# cslr_tetb register map
Vendor: Texas Instruments
Peripheral module from a debugger description file (folder TCI6484_C6457).
Registers are 32-bit, access not given, reset 0x0 unless marked. A register's access mark holds for its fields unless they carry their own. Offsets are as the file gives them; lines under a group give offsets from that group; [hi:lo] are bit positions; {n}, {i} and the like mark numbered series; 'fields as' and 'values as' point back to an identical list; <NAME> marks a mode.

## TETB — TI External Trace Buffer
0x04 RDP ro reset 0x200 — RAM Depth Register
  [31:0] RDP — RAM Depth
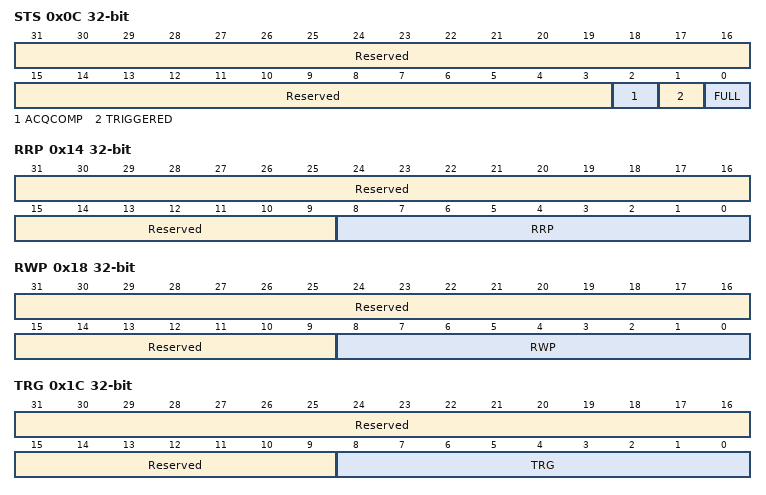
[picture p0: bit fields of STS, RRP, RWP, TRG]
0x0C STS — Status Register
  [31:3] Reserved — (access N)
  [2] ACQCOMP ro — Acquisition complete
  [1] TRIGGERED ro — Trigger bit set when a trigger has been observed
  [0] FULL ro — RAM Full (RAM write pointer has wrapped around)
0x10 RRD ro — RAM Read Data
  [31:0] RRD — RAM read Data
0x14 RRP — RAM Read Pointer register
  [31:9] Reserved — (access N)
  [8:0] RRP rw — RAM pointer register
0x18 RWP — RAM Write Pointer register
  [31:9] Reserved — (access N)
  [8:0] RWP rw — RAM write pointer register
0x1C TRG — Trigger Counter Register
  [31:9] Reserved — (access N)
  [8:0] TRG rw — Trigger counter register
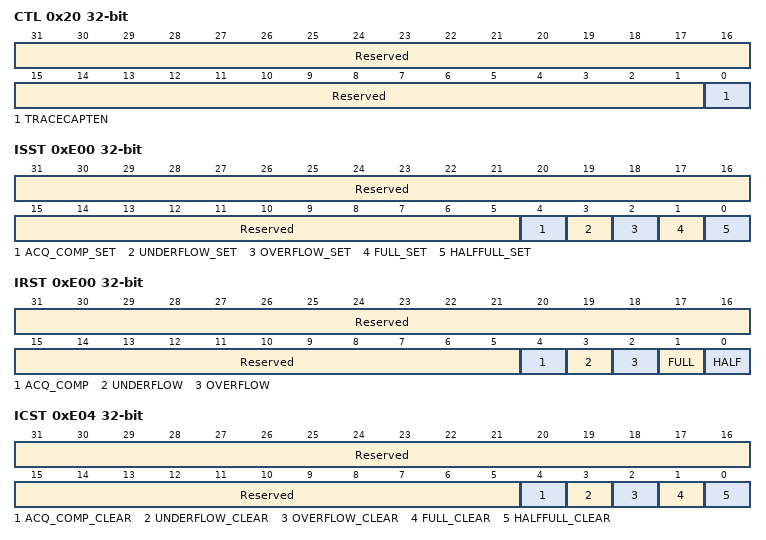
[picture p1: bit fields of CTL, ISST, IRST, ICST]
0x20 CTL — Control Register
  [31:1] Reserved — (access N)
  [0] TRACECAPTEN rw — TETB Trace Capture Enable/Disable
    0=DISABLE; 1=ENABLE
0x24 RWD rw — RAM write Data Register
  [31:0] RWD — Data written to TETB trace RAM
0xA00 RBD ro — RAM write Data Register
  [31:0] RBD — Data read from the TETB Trace RAM
0xE00 ISST — Interrupt Set Shadow Register
  [31:5] Reserved — (access N)
  [4] ACQ_COMP_SET wo — Acquisition complete
    1=SET (Set the AcqComp bit in the IRST)
  [3] UNDERFLOW_SET wo — It is set when RWP crosses the RRP
    1=SET (Set the underflow bit in the IRST)
  [2] OVERFLOW_SET wo — It is set when RWP crosses the RRP
    1=SET (Set the overflow bit in the IRST)
  [1] FULL_SET wo — It is set when RWP is rolls over from the maximum value back to 0. It is reset when the RRP rolls over from the maximum value back to 0.
    1=SET (Set the full bit in the IRST)
  [0] HALFFULL_SET wo — Indicates that the RAM is half full. It gets reset when the RRP crosses the half way point
    1=SET (Set the half full bit in the IRST)
0xE00 IRST — Interrupt Raw Status Register
  [31:5] Reserved — (access N)
  [4] ACQ_COMP ro — Acquisition complete
  [3] UNDERFLOW ro — It is set when RWP crosses the RRP
  [2] OVERFLOW ro — It is set when RWP crosses the RRP
  [1] FULL ro — It is set when RWP is rolls over from the maximum value back to 0. It is reset when the RRP rolls over from the maximum value back to 0.
  [0] HALF FULL ro — Indicates that the RAM is half full. It gets reset when the RRP crosses the half way point
0xE04 ICST — Interrupt Set Shadow Register
  [31:5] Reserved — (access N)
  [4] ACQ_COMP_CLEAR wo — Acquisition complete
    1=CLEAR (Clear the AcqComp bit in the IRST)
  [3] UNDERFLOW_CLEAR wo — It is set when RWP crosses the RRP
    1=CLEAR (Clear the underflow bit in the IRST)
  [2] OVERFLOW_CLEAR wo — It is set when RWP crosses the RRP
    1=CLEAR (Clear the overflow bit in the IRST)
  [1] FULL_CLEAR wo — It is set when RWP is rolls over from the maximum value back to 0. It is reset when the RRP rolls over from the maximum value back to 0.
    1=CLEAR (Clear the full bit in the IRST)
  [0] HALFFULL_CLEAR wo — Indicates that the RAM is half full. It gets reset when the RRP crosses the half way point
    1=CLEAR (Clear the half full bit in the IRST)
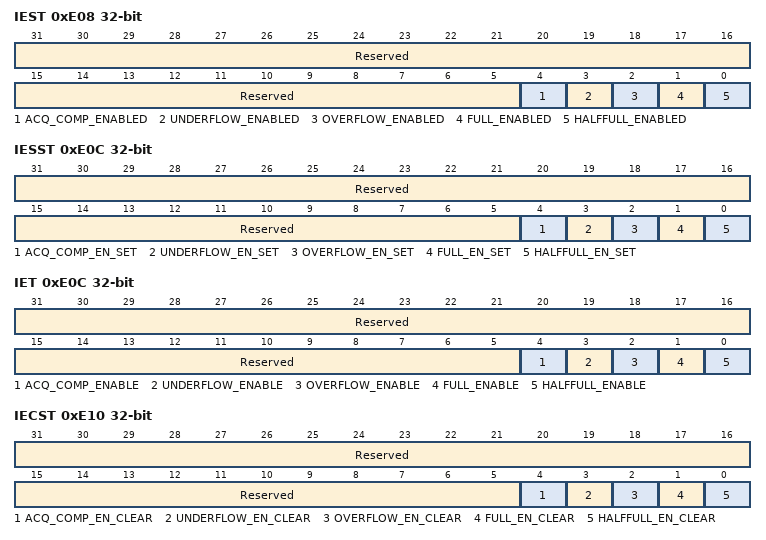
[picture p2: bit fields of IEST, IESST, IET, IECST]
0xE08 IEST — IRST qualified by the Interrupt Enable Register
  [31:5] Reserved — (access N)
  [4] ACQ_COMP_ENABLED ro — Qualified Acq_comp bit
  [3] UNDERFLOW_ENABLED ro — Qualified Underflow bit
  [2] OVERFLOW_ENABLED ro — Qualified Overflow bit
  [1] FULL_ENABLED ro — Qualified Full bit
  [0] HALFFULL_ENABLED ro — Qualified Half Full bit
0xE0C IESST — Enable interrupts in the IET register
  [31:5] Reserved — (access N)
  [4] ACQ_COMP_EN_SET wo — Set the Acquisition Complete bit in the IET
    1=SET (Set the Acquisition Comp bit in the IET)
  [3] UNDERFLOW_EN_SET wo — Set the underflow bit in the IET
    1=SET (set the underflow bit in the IET)
  [2] OVERFLOW_EN_SET wo — Set the overflow bit in the IET
    1=SET (Set the overflow bit in the IET)
  [1] FULL_EN_SET wo — Set the full bit in the IET
    1=SET (Set the full bit in the IET)
  [0] HALFFULL_EN_SET wo — Set the half full bit in the IET
    1=SET (Set the half full bit in the IET)
0xE0C IET — Interrupt Enable Register
  [31:5] Reserved — (access N)
  [4] ACQ_COMP_ENABLE ro — Enable Acq_comp bit
  [3] UNDERFLOW_ENABLE ro — Enable Underflow bit
  [2] OVERFLOW_ENABLE ro — Enable Overflow bit
  [1] FULL_ENABLE ro — Enable Full bit
  [0] HALFFULL_ENABLE ro — Enable Half Full bit
0xE10 IECST — Enable interrupts in the IET register
  [31:5] Reserved — (access N)
  [4] ACQ_COMP_EN_CLEAR wo — Clear the Acquisition Complete bit in the IET
    1=CLEAR (Clear the Acquisition bit in the IET)
  [3] UNDERFLOW_EN_CLEAR wo — Clear the underflow bit in the IET
    1=CLEAR (Clear the underflow bit in the IET)
  [2] OVERFLOW_EN_CLEAR wo — Clear the overflow bit in the IET
    1=CLEAR (Clear the overflow bit in the IET)
  [1] FULL_EN_CLEAR wo — Clear the full bit in the IET
    1=CLEAR (Clear the full bit in the IET)
  [0] HALFFULL_EN_CLEAR wo — Clear the half full bit in the IET
    1=CLEAR (Clear the half full bit in the IET)
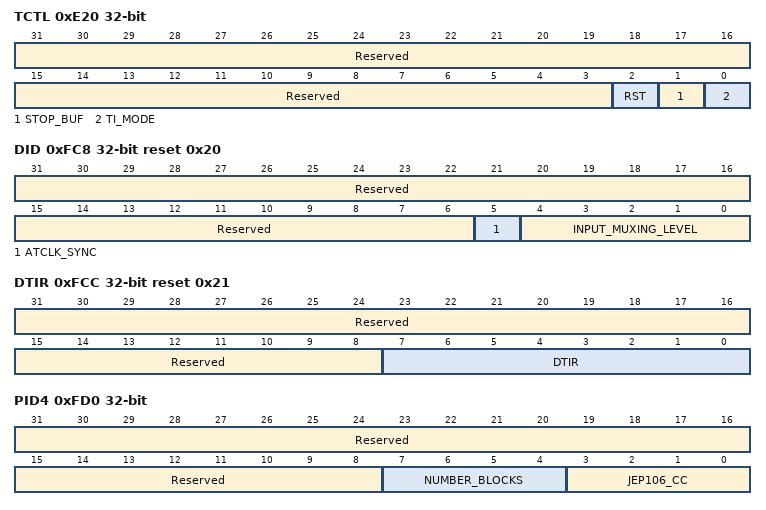
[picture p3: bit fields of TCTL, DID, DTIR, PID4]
0xE20 TCTL — TI Specific Control Register
  [31:3] Reserved — (access N)
  [2] RST wo — Reset TETB
    0=RESET_NO (Do not reset the TETB); 1=RESET_YES (Reset the TETB)
  [1] STOP_BUF rw — Buffer Mode
    0=CIRCULAR_MODE (Circular Buffer Mode); 1=STOP_MODE (Stop Buffer Mode)
  [0] TI_MODE rw — The behavior of the RRD and RRP changes depending on this bit
0xFC8 DID reset 0x20 — Device ID
  [31:6] Reserved — (access N)
  [5] ATCLK_SYNC ro — if TETB is syncronous to ATCLK
  [4:0] INPUT_MUXING_LEVEL ro — Only 0x00 is supported
0xFCC DTIR reset 0x21 — Device Type Identification Register
  [31:8] Reserved — (access N)
  [7:0] DTIR ro — Indicates it is a trace sink
0xFD0 PID4 — Peripheral Identification 4 Register
  [31:8] Reserved — (access N)
  [7:4] NUMBER_BLOCKS ro — Number of additional 4KB memory blocks expressed in powers of 2
  [3:0] JEP106_CC ro — JEP106 Continuation Code
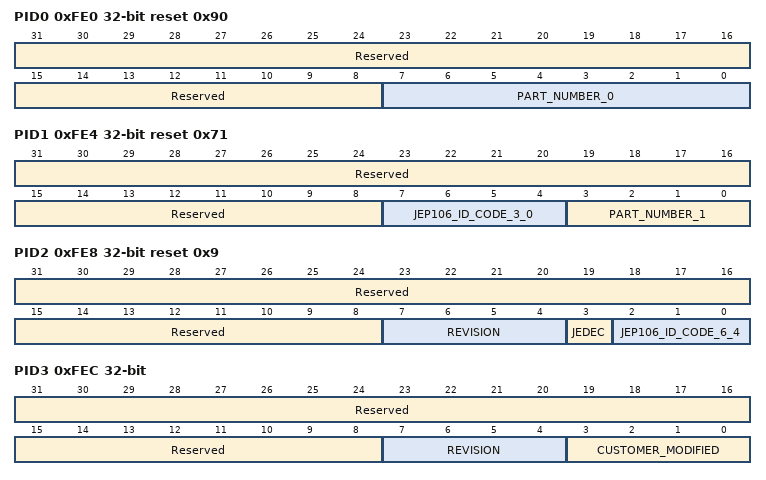
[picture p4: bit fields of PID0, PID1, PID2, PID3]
0xFE0 PID0 reset 0x90 — Peripheral Identification 0 Register
  [31:8] Reserved — (access N)
  [7:0] PART_NUMBER_0 ro — Part Number 0 (Middle and Lower BCD value of Device Number)
0xFE4 PID1 reset 0x71 — Peripheral Identification 1 Register
  [31:8] Reserved — (access N)
  [7:4] JEP106_ID_CODE_3_0 ro — JEP106 identity code [3:0]
  [3:0] PART_NUMBER_1 ro — Part Number 1 (Upper BCD value of Device Number)
0xFE8 PID2 reset 0x9 — Peripheral Identification 2 Register
  [31:8] Reserved — (access N)
  [7:4] REVISION ro — Revision Number of Peripheral
  [3] JEDEC ro — Indicates that a JEDEC assigned value is used
  [2:0] JEP106_ID_CODE_6_4 ro — JEP106 identity code [6:4]
0xFEC PID3 — Peripheral Identification 3 Register
  [31:8] Reserved — (access N)
  [7:4] REVISION ro — RevAnd (at top level)
  [3:0] CUSTOMER_MODIFIED ro
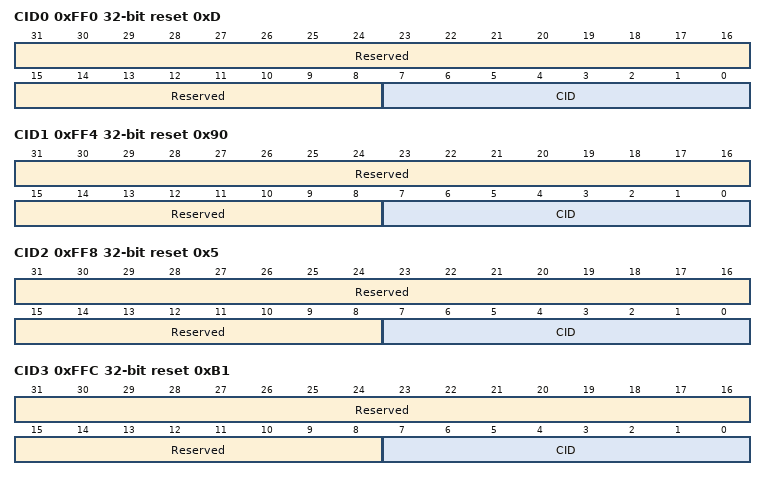
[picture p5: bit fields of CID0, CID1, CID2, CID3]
0xFF0 CID0 reset 0xD — Component ID0 Register
  [31:8] Reserved — (access N)
  [7:0] CID ro — This register shall return Preamble value 0x0D
0xFF4 CID1 reset 0x90 — Component ID1 Register
  [31:8] Reserved — (access N)
  [7:0] CID ro — This register shall return Preamble value 0x90
0xFF8 CID2 reset 0x5 — Component ID2 Register
  [31:8] Reserved — (access N)
  [7:0] CID ro — This register shall return Preamble value 0x05
0xFFC CID3 reset 0xB1 — Component ID3 Register
  [31:8] Reserved — (access N)
  [7:0] CID ro — This register shall return Preamble value 0xB1
